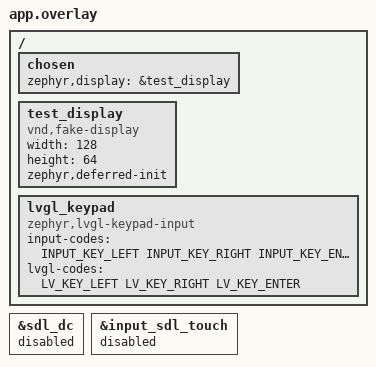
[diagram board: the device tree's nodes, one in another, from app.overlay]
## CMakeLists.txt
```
cmake_minimum_required(VERSION 3.20.0)
# O display de teste tem binding próprio, em dts/bindings.
list(APPEND DTS_ROOT ${CMAKE_CURRENT_LIST_DIR})
find_package(Zephyr REQUIRED HINTS $ENV{ZEPHYR_BASE})
project(vitrolinha_display_test LANGUAGES C)
include(${CMAKE_CURRENT_LIST_DIR}/../vitrolinha_test.cmake)
target_sources(app PRIVATE
  src/fake_display.c
  src/main.c
)
```

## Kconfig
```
# Este teste escolhe a origem da biblioteca: a pasta do computador é a única
# implementação em que dá para provocar biblioteca vazia, ausente e cheia.

rsource "../../Kconfig.vitrolinha"

source "Kconfig.zephyr"
```

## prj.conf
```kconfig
CONFIG_ZTEST=y
CONFIG_ASSERT=y
CONFIG_LOG=y
CONFIG_VITROLINHA_STORAGE_HOST=y

# O display de teste nasce sem inicializar — `zephyr,deferred-init` no
# app.overlay, sem opção de Kconfig —, para que o teste veja display_init()
# recusar um display que não está pronto antes de chamar device_init().
CONFIG_DISPLAY=y

# Sem janela nem SDL: o display é o de teste, e o toque SDL do native_sim
# dependeria da janela que ele desligou.
CONFIG_SDL_DISPLAY=n
CONFIG_INPUT=y
CONFIG_INPUT_SDL_TOUCH=n

# Cada input_report_key() chega ao keypad do LVGL antes de voltar, sem
# depender de a thread do subsistema input rodar.
CONFIG_INPUT_MODE_SYNCHRONOUS=y

# O LVGL é posto de pé pelo teste, depois de o display inicializar, e o
# laço é o próprio teste quem roda, com lv_timer_handler() e lv_indev_read().
CONFIG_LVGL=y
CONFIG_LV_Z_AUTO_INIT=n
CONFIG_LV_COLOR_DEPTH_1=y
CONFIG_LV_Z_MONOCHROME_CONVERSION_BUFFER=y
CONFIG_LV_Z_VDB_SIZE=100
CONFIG_LV_Z_MEM_POOL_SIZE=24576
CONFIG_LV_FONT_UNSCII_8=y
CONFIG_LV_FONT_DEFAULT_UNSCII_8=y
```

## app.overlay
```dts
/*
 * O display e o dispositivo de entrada da interface, trocados por versões
 * que o teste controla.
 *
 * SPDX-License-Identifier: Apache-2.0
 */

#include <zephyr/dt-bindings/input/input-event-codes.h>
#include <zephyr/dt-bindings/lvgl/lvgl.h>

&sdl_dc {
	status = "disabled";
};

&input_sdl_touch {
	status = "disabled";
};

/ {
	chosen {
		zephyr,display = &test_display;
	};

	/* O tamanho do OLED. Nasce sem inicializar: ver prj.conf. */
	test_display: test_display {
		compatible = "vnd,fake-display";
		width = <128>;
		height = <64>;
		zephyr,deferred-init;
	};

	/*
	 * O mesmo keypad do simulador, mas sem a propriedade `input`: assim
	 * aceita os eventos que o teste publica sem dispositivo de origem.
	 */
	lvgl_keypad: lvgl_keypad {
		compatible = "zephyr,lvgl-keypad-input";
		input-codes = <INPUT_KEY_LEFT INPUT_KEY_RIGHT INPUT_KEY_ENTER>;
		lvgl-codes = <LV_KEY_LEFT LV_KEY_RIGHT LV_KEY_ENTER>;
	};
};
```

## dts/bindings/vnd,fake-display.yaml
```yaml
description: |
  Display de teste: monocromático, aceita qualquer escrita e devolve em
  display_blanking_off() o valor que o teste mandar.

compatible: "vnd,fake-display"

include: display-controller.yaml
```

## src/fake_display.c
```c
/**
 * @file fake_display.c
 * @brief Display de teste: 128x64, monocromático, guarda o último quadro.
 *
 * Existe porque o `zephyr,dummy-dc` sempre aceita desligar o blanking, e a
 * interface tem um caminho para cada resposta: sucesso, -ENOSYS e erro. O
 * quadro guardado deixa os testes conferirem o desenho pixel a pixel, sem a
 * placa, e imprimi-lo para quem quiser olhar.
 */

#define DT_DRV_COMPAT vnd_fake_display

#include "fake_display.h"

#include <stdlib.h>
#include <string.h>

#include <zephyr/device.h>
#include <zephyr/drivers/display.h>
#include <zephyr/sys/printk.h>

#define WIDTH  DT_INST_PROP(0, width)
#define HEIGHT DT_INST_PROP(0, height)

/**
 * @brief O quadro, no formato do SSD1306: páginas de 8 linhas, um byte por
 *        coluna, o bit 0 no alto. Em MONO01 o bit 1 é branco.
 */
static uint8_t frame[HEIGHT / 8][WIDTH];

static int blanking_off_result;

void fake_display_set_blanking_off_result(int result)
{
	blanking_off_result = result;
}

bool fake_display_lit(int x, int y)
{
	/* Branco no LVGL é bit 1 em MONO01, e sai apagado no OLED. */
	return ((frame[y / 8][x] >> (y % 8)) & 1U) == 0U;
}

void fake_display_dump(const char *title)
{
	if (getenv("VITROLINHA_TELA") == NULL) {
		return;
	}

	printk("=== %s\n", title);
	for (int y = 0; y < HEIGHT; y++) {
		char line[WIDTH + 1];

		for (int x = 0; x < WIDTH; x++) {
			line[x] = fake_display_lit(x, y) ? '#' : '.';
		}
		line[WIDTH] = '\0';
		printk("%02d %s\n", y, line);
	}
}

static int fake_blanking_on(const struct device *dev)
{
	ARG_UNUSED(dev);
	return 0;
}

static int fake_blanking_off(const struct device *dev)
{
	ARG_UNUSED(dev);
	return blanking_off_result;
}

static int fake_write(const struct device *dev, const uint16_t x, const uint16_t y,
		      const struct display_buffer_descriptor *desc, const void *buf)
{
	const uint8_t *in = buf;

	ARG_UNUSED(dev);

	/* O LVGL arredonda as áreas a páginas inteiras, então y é múltiplo de 8. */
	for (uint16_t page = 0; page < desc->height / 8U; page++) {
		memcpy(&frame[y / 8U + page][x], &in[page * desc->pitch], desc->width);
	}
	return 0;
}

static void fake_get_capabilities(const struct device *dev,
				  struct display_capabilities *capabilities)
{
	ARG_UNUSED(dev);

	memset(capabilities, 0, sizeof(*capabilities));
	capabilities->x_resolution = WIDTH;
	capabilities->y_resolution = HEIGHT;
	capabilities->supported_pixel_formats = PIXEL_FORMAT_MONO01;
	capabilities->current_pixel_format = PIXEL_FORMAT_MONO01;
	capabilities->screen_info = SCREEN_INFO_MONO_VTILED;
}

static int fake_set_pixel_format(const struct device *dev,
				 const enum display_pixel_format format)
{
	ARG_UNUSED(dev);
	return format == PIXEL_FORMAT_MONO01 ? 0 : -ENOTSUP;
}

static DEVICE_API(display, fake_display_api) = {
	.blanking_on = fake_blanking_on,
	.blanking_off = fake_blanking_off,
	.write = fake_write,
	.get_capabilities = fake_get_capabilities,
	.set_pixel_format = fake_set_pixel_format,
};

static int fake_display_init(const struct device *dev)
{
	ARG_UNUSED(dev);
	return 0;
}

DEVICE_DT_INST_DEFINE(0, fake_display_init, NULL, NULL, NULL, POST_KERNEL,
		      CONFIG_DISPLAY_INIT_PRIORITY, &fake_display_api);
```

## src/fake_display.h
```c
/**
 * @file fake_display.h
 * @brief Display de teste: guarda o quadro, e o blanking responde o que o
 *        teste mandar.
 */

#ifndef VITROLINHA_TEST_FAKE_DISPLAY_H_
#define VITROLINHA_TEST_FAKE_DISPLAY_H_

#include <stdbool.h>

/**
 * @brief Escolhe o que o próximo display_blanking_off() devolve.
 *
 * @param result 0, -ENOSYS (o driver não implementa blanking) ou um erro.
 */
void fake_display_set_blanking_off_result(int result);

/**
 * @brief Diz se o pixel aparece aceso no OLED da ZBook.
 *
 * Aceso é o que o LVGL pinta de preto — o texto, o destaque, o preenchimento
 * da barra. O branco do LVGL, fundo do tema mono, sai apagado no SSD1306.
 * Vale o último quadro escrito; chamar lv_refr_now() antes.
 */
bool fake_display_lit(int x, int y);

/**
 * @brief Imprime o último quadro no console, `#` aceso e `.` apagado.
 *
 * Para olhar a tela sem a placa: rode o teste com VITROLINHA_TELA=1 no
 * ambiente. Sem a variável, não imprime nada.
 *
 * @param title Linha de título antes do quadro.
 */
void fake_display_dump(const char *title);

#endif /* VITROLINHA_TEST_FAKE_DISPLAY_H_ */
```
